# Cortex-M4_RTSM register map
Vendor: ARM Ltd.
Cortex-M4_RTSM core descriptions, generated from ARM develloper studio
CPU: Cortex-M4_RTSM r0p0, little endian, MPU, FPU, VTOR, vendor SysTick, 8 interrupt priority bits
Registers are 32-bit, read-write, no defined reset value unless marked. A register's access mark holds for its fields unless they carry their own. Offsets are from the block's base; lines under a group give offsets from that group; [hi:lo] are bit positions; {n}, {i} and the like mark numbered series; 'fields as' and 'values as' point back to an identical list; <NAME> marks a mode.

## Memory map
? Control size 0x260 — System Control registers
? ID size 0x1C0 — ID registers
? FPE size 0xA0 — System Control registers for the FP extension
? SysTick size 0x80 — System Timer registers
? NVIC size 0xCA0 — Nested Vectored Interrupt Controller registers
? MPU size 0x160 — Memory Protection Unit

## ID — ID registers
Base ?
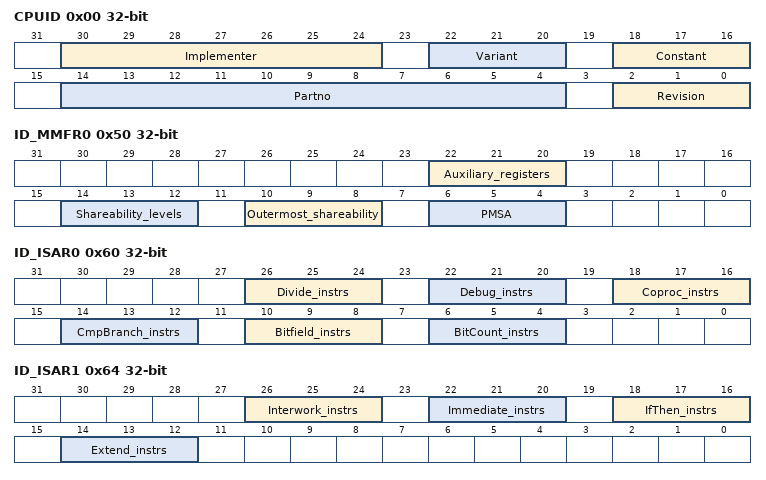
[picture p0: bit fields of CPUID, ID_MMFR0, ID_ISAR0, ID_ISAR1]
0x00 CPUID ro
  [30:24] Implementer — Implementer code
  [22:20] Variant — Implementation defined
  [18:16] Constant — Indicates the architecture
  [14:4] Partno — Indicates part number
  [2:0] Revision — Indicates revision
0x40 ID_PFR0 ro
  [6:4] State1 — Thumb instruction set support
0x44 ID_PFR1 ro
  [10:8] M_Profile — M profile programmers' model
0x48 ID_DFR0 ro
  [22:20] M_Profile — Debug model, M profile
0x4C ID_AFR0 ro
0x50 ID_MMFR0 ro
  [22:20] Auxiliary_registers — Indicates support for Auxiliary registers
  [14:12] Shareability_levels — Indicates the number of shareability levels implemented
  [10:8] Outermost_shareability — Indicates the outermost shareability domain implemented
  [6:4] PMSA — Indicates support for a PMSA
0x54 ID_MMFR1 ro
0x58 ID_MMFR2 ro
  [26:24] WFI — Indicates support for wait-for-interrupt stalling.
0x5C ID_MMFR3 ro
0x60 ID_ISAR0 ro
  [26:24] Divide_instrs — Indicates the supported divide instructions
  [22:20] Debug_instrs — Indicates the supported debug instructions
  [18:16] Coproc_instrs — Indicates the supported coprocessor instructions
  [14:12] CmpBranch_instrs — Indicates support for combined compare and branch instructions.
  [10:8] Bitfield_instrs — Indicates support for bitfield instructions.
  [6:4] BitCount_instrs — Indicates support for bit counting instructions.
0x64 ID_ISAR1 ro
  [26:24] Interwork_instrs — Indicates support for instructions that branch between ARM and Thumb code.
  [22:20] Immediate_instrs — Indicates support for immediate instructions.
  [18:16] IfThen_instrs — Indicates support for IfThen instructions.
  [14:12] Extend_instrs — Indicates support for sign or zero extend instructions.
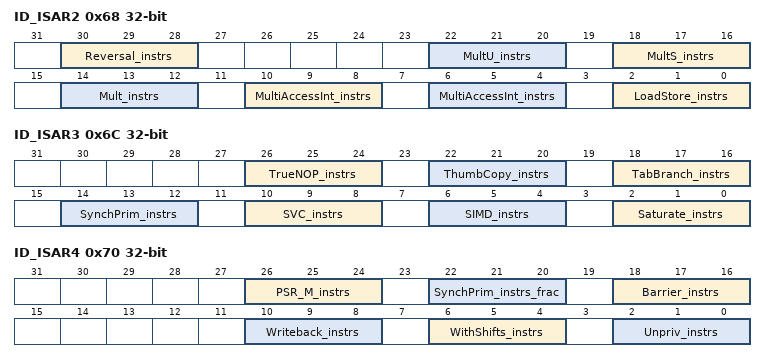
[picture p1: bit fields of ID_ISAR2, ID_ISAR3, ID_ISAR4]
0x68 ID_ISAR2 ro
  [30:28] Reversal_instrs — Indicates the supported reversal instructions.
  [22:20] MultU_instrs — Indicates the supported advanced unsigned multiply instructions.
  [18:16] MultS_instrs — Indicates the supported advanced signed multiply instructions.
  [14:12] Mult_instrs — Indicates the supported additional multiply instructions.
  [10:8] MultiAccessInt_instrs — Indicates the supported multi-access interruptible instructions.
  [6:4] MultiAccessInt_instrs — Indicates the supported memory hint instructions.
  [2:0] LoadStore_instrs — Indicates the supported additional load and store instructions.
0x6C ID_ISAR3 ro
  [26:24] TrueNOP_instrs — Indicates support for true NOP instructions.
  [22:20] ThumbCopy_instrs — Indicates support for Thumb copy instructions.
  [18:16] TabBranch_instrs — Indicates support for table branch instructions.
  [14:12] SynchPrim_instrs — Indicates support for synchronization primitive instructions.
  [10:8] SVC_instrs — Indicates support for SVC instructions.
  [6:4] SIMD_instrs — Indicates support for Single Instruction Multiple Data (SIMD) instructions.
  [2:0] Saturate_instrs — Indicates support for saturate instructions.
0x70 ID_ISAR4 ro
  [26:24] PSR_M_instrs — Indicates support for saturate instructions.
  [22:20] SynchPrim_instrs_frac — Indicates support for Synchronization Primitives
  [18:16] Barrier_instrs — Indicates the supported barrier instructions.
  [10:8] Writeback_instrs — Indicates support for Writeback addressing modes
  [6:4] WithShifts_instrs — Indicates the support for instructions with shifts:
  [2:0] Unpriv_instrs — Indicates the supported unprivileged instructions
